# PY32F071xx register map
Vendor: Puya; Series: PY32F0; File version: 1.0.0
CPU: CM0+ r0p1, little endian, no MPU, no FPU, 4 interrupt priority bits
Registers are 32-bit, read-write, reset 0x0 unless marked. A register's access mark holds for its fields unless they carry their own. Offsets are from the block's base; [hi:lo] are bit positions.

## COMP1 — Comparator 1
Base 0x40010200
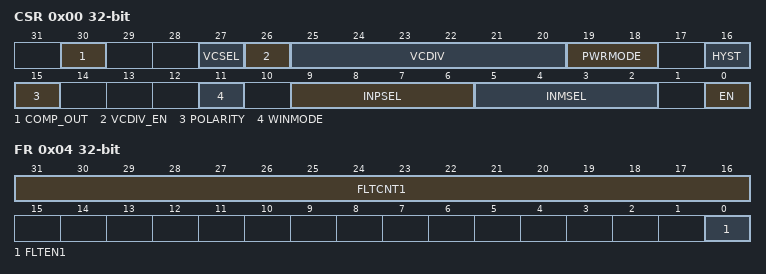
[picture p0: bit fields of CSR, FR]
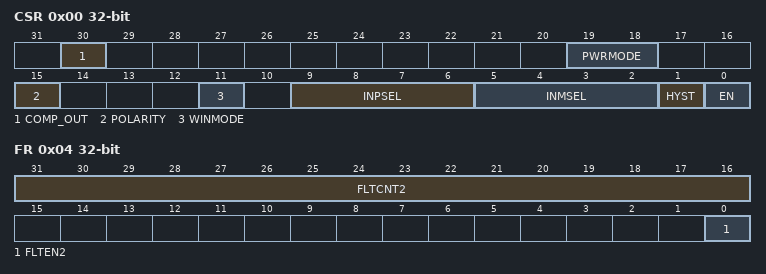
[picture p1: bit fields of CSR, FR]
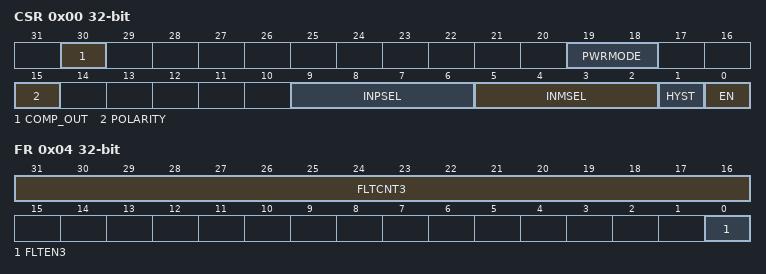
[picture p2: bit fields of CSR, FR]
0x00 CSR — COMP control and status register
  [30] COMP_OUT — Comparator output status
  [27] VCSEL
  [26] VCDIV_EN
  [25:20] VCDIV
    1=0; 2=1; 4=2; 8=3; 16=4; 32=5
  [19:18] PWRMODE — Comparator power mode selector
    1=0; 2=1
  [16] HYST — Comparator hysteresis enable selector
  [15] POLARITY — Comparator polarity selector
  [11] WINMODE — Comparator non-inverting input selector for window mode
  [9:6] INPSEL — Comparator signal selector for non-inverting input
    1=0; 2=1; 4=2; 8=3
  [5:2] INMSEL — Comparator signal selector for inverting input INM
  [0] EN — COMP enable bit
0x04 FR — Comparator Filter register
  [31:16] FLTCNT1 — Comparator filter and counter
  [0] FLTEN1 — Filter enable bit

## COMP2 — Comparator2
Base 0x40010210
0x00 CSR — COMP control and status register
  [30] COMP_OUT — Comparator output status
  [19:18] PWRMODE — Comparator power mode selector
    1=0; 2=1
  [15] POLARITY — Comparator polarity selector
  [11] WINMODE — Comparator non-inverting input selector for window mode
  [9:6] INPSEL — Comparator signal selector for non-inverting input
    1=0; 2=1; 4=2; 8=3
  [5:2] INMSEL — Comparator signal selector for inverting input INM
  [1] HYST — Comparator hysteresis enable selector
  [0] EN — COMP enable bit
0x04 FR — Comparator Filter register
  [31:16] FLTCNT2 — Comparator filter and counter
  [0] FLTEN2 — Filter enable bit

## COMP3 — Comparator3
Base 0x40010220
0x00 CSR — COMP control and status register
  [30] COMP_OUT — Comparator output status
  [19:18] PWRMODE — Comparator power mode selector
    1=0; 2=1
  [15] POLARITY — Comparator polarity selector
  [9:6] INPSEL — Comparator signal selector for non-inverting input
    1=0; 2=1; 4=2; 8=3
  [5:2] INMSEL — Comparator signal selector for inverting input INM
  [1] HYST — Comparator hysteresis enable selector
  [0] EN — COMP enable bit
0x04 FR — Comparator Filter register
  [31:16] FLTCNT3 — Comparator filter and counter
  [0] FLTEN3 — Filter enable bit

## CRC — CRC calculation unit
Base 0x40023000
0x00 DR reset 0xFFFFFFFF — Data register
  [31:0] DR — Data Register
0x04 IDR — Independent Data register
  [7:0] IDR
0x08 CR wo — Control register
  [0] RESET — Reset bit

## CTC
Base 0x40006C00
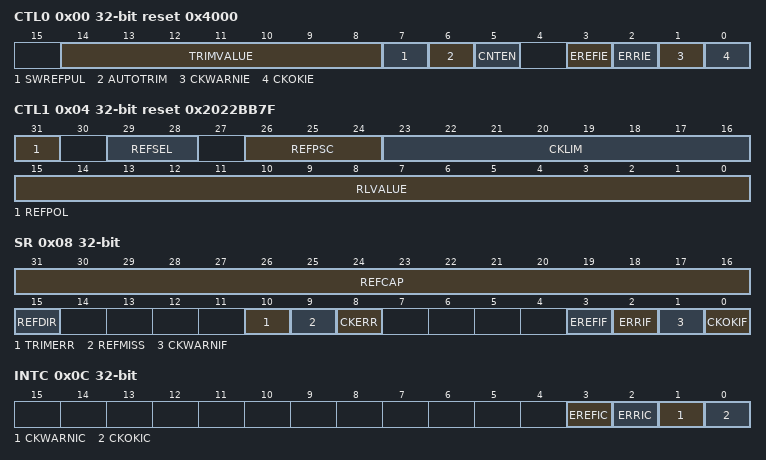
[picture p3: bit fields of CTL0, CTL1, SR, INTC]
0x00 CTL0 reset 0x4000
  [14:8] TRIMVALUE, [7] SWREFPUL wo, [6] AUTOTRIM, [5] CNTEN, [3] EREFIE, [2] ERRIE, [1] CKWARNIE, [0] CKOKIE
0x04 CTL1 reset 0x2022BB7F
  [31] REFPOL
  [29:28] REFSEL
    1=0; 2=1
  [26:24] REFPSC
    1=0; 2=1; 4=2
  [23:16] CKLIM
  [15:0] RLVALUE
0x08 SR ro
  [31:16] REFCAP, [15] REFDIR, [10] TRIMERR, [9] REFMISS, [8] CKERR, [3] EREFIF, [2] ERRIF, [1] CKWARNIF, [0] CKOKIF
0x0C INTC wo
  [3] EREFIC, [2] ERRIC, [1] CKWARNIC, [0] CKOKIC

## DAC
Base 0x40007400
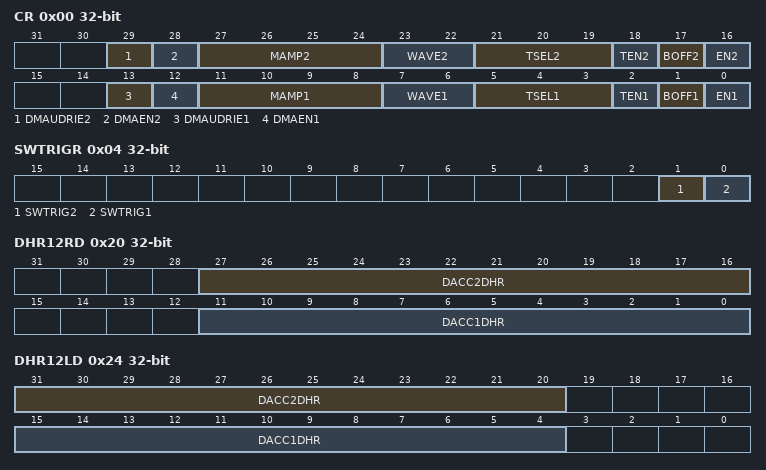
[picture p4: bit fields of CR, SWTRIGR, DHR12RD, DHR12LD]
0x00 CR
  [29] DMAUDRIE2
  [28] DMAEN2
  [27:24] MAMP2
    1=0; 2=1; 4=2; 8=3
  [23:22] WAVE2
    1=0; 2=1
  [21:19] TSEL2
    1=0; 2=1; 4=2
  [18] TEN2
  [17] BOFF2
  [16] EN2
  [13] DMAUDRIE1
  [12] DMAEN1
  [11:8] MAMP1
    1=0; 2=1; 4=2; 8=3
  [7:6] WAVE1
    1=0; 2=1
  [5:3] TSEL1
    1=0; 2=1; 4=2
  [2] TEN1
  [1] BOFF1
  [0] EN1
0x04 SWTRIGR
  [1] SWTRIG2, [0] SWTRIG1
0x08 DHR12R1
  [11:0] DACC1DHR
0x0C DHR12L1
  [15:4] DACC1DHR
0x10 DHR8R1
  [7:0] DACC1DHR
0x14 DHR12R2
  [11:0] DACC2DHR
0x18 DHR12L2
  [15:4] DACC2DHR
0x1C DHR8R2
  [7:0] DACC2DHR
0x20 DHR12RD
  [27:16] DACC2DHR, [11:0] DACC1DHR
0x24 DHR12LD
  [31:20] DACC2DHR, [15:4] DACC1DHR
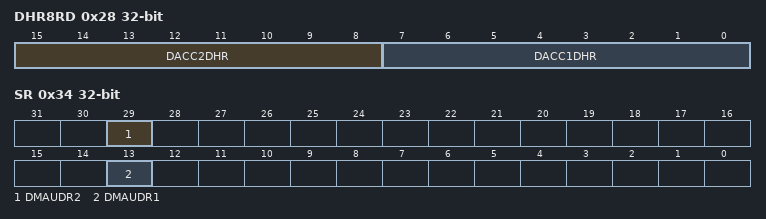
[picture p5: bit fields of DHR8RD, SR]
0x28 DHR8RD
  [15:8] DACC2DHR, [7:0] DACC1DHR
0x2C DOR1 ro
  [11:0] DACC1DOR
0x30 DOR2 ro
  [11:0] DACC2DOR
0x34 SR
  [29] DMAUDR2, [13] DMAUDR1
